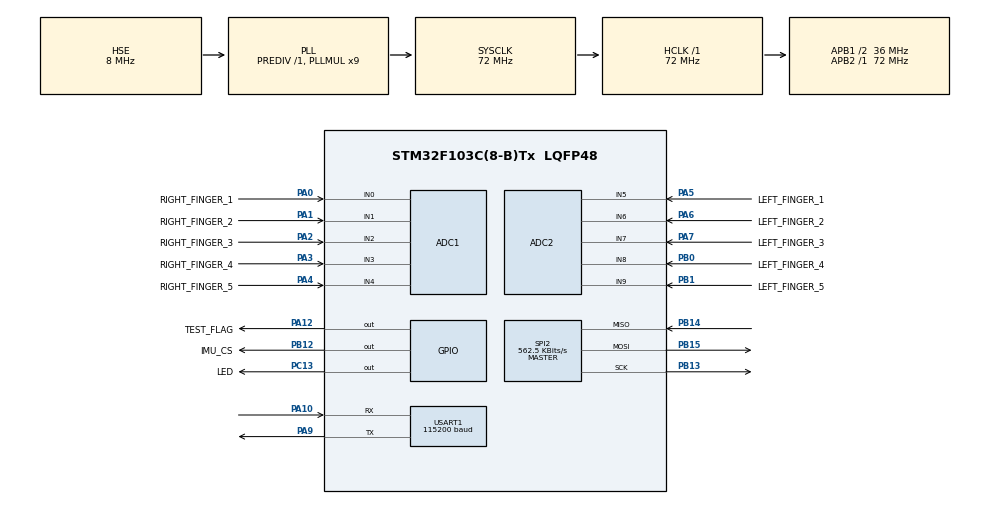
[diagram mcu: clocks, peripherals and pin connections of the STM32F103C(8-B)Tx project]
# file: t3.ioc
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ADC1.ContinuousConvMode=DISABLE
ADC1.DataAlign=ADC_DATAALIGN_RIGHT
ADC1.DiscontinuousConvMode=DISABLE
ADC1.EnableRegularConversion=DISABLE
ADC1.InjNumberOfConversion=0
ADC1.ScanConvMode=ADC_SCAN_DISABLE
ADC1.master=1
ADC2.Channel-0\#ChannelRegularConversion=ADC_CHANNEL_9
ADC2.ContinuousConvMode=DISABLE
ADC2.DataAlign=ADC_DATAALIGN_RIGHT
ADC2.DiscontinuousConvMode=DISABLE
ADC2.EnableAnalogWatchDog=false
ADC2.EnableRegularConversion=ENABLE
ADC2.ExternalTrigConv=ADC_SOFTWARE_START
ADC2.InjNumberOfConversion=0
ADC2.NbrOfConversion=1
ADC2.Rank-0\#ChannelRegularConversion=1
ADC2.SamplingTime-0\#ChannelRegularConversion=ADC_SAMPLETIME_1CYCLE_5
ADC2.ScanConvMode=ADC_SCAN_DISABLE
Mcu.Family=STM32F1
Mcu.Name=STM32F103C(8-B)Tx
Mcu.Package=LQFP48
NVIC.PriorityGroup=NVIC_PRIORITYGROUP_4
NVIC.TIM2_IRQn=true\:0\:0\:false\:false\:true\:true
PA0-WKUP.GPIO_Label=RIGHT_FINGER_1
PA0-WKUP.Signal=ADCx_IN0
PA1.GPIO_Label=RIGHT_FINGER_2
PA1.Signal=ADCx_IN1
PA10.Mode=Asynchronous
PA10.Signal=USART1_RX
PA12.GPIO_Label=TEST_FLAG
PA12.Signal=GPIO_Output
PA2.GPIO_Label=RIGHT_FINGER_3
PA2.Signal=ADCx_IN2
PA3.GPIO_Label=RIGHT_FINGER_4
PA3.Signal=ADCx_IN3
PA4.GPIO_Label=RIGHT_FINGER_5
PA4.Signal=ADCx_IN4
PA5.GPIO_Label=LEFT_FINGER_1
PA5.Signal=ADCx_IN5
PA6.GPIO_Label=LEFT_FINGER_2
PA6.Signal=ADCx_IN6
PA7.GPIO_Label=LEFT_FINGER_3
PA7.Signal=ADCx_IN7
PA9.Mode=Asynchronous
PA9.Signal=USART1_TX
PB0.GPIO_Label=LEFT_FINGER_4
PB0.Signal=ADCx_IN8
PB1.GPIO_Label=LEFT_FINGER_5
PB1.Signal=ADCx_IN9
PB12.GPIO_Label=IMU_CS
PB12.Signal=GPIO_Output
PB13.GPIO_Speed=GPIO_SPEED_FREQ_HIGH
PB13.Mode=Full_Duplex_Master
PB13.Signal=SPI2_SCK
PB14.GPIO_PuPd=GPIO_PULLDOWN
PB14.Mode=Full_Duplex_Master
PB14.Signal=SPI2_MISO
PB15.GPIO_Speed=GPIO_SPEED_FREQ_HIGH
PB15.Mode=Full_Duplex_Master
PB15.Signal=SPI2_MOSI
PC13-TAMPER-RTC.GPIO_Label=LED
PC13-TAMPER-RTC.Signal=GPIO_Output
PD0-OSC_IN.Mode=HSE-External-Oscillator
PD0-OSC_IN.Signal=RCC_OSC_IN
PD1-OSC_OUT.Mode=HSE-External-Oscillator
PD1-OSC_OUT.Signal=RCC_OSC_OUT
ProjectManager.HeapSize=0x200
ProjectManager.StackSize=0x400
ProjectManager.TargetToolchain=MDK-ARM V5
RCC.ADCPresc=RCC_ADCPCLK2_DIV6
RCC.AHBFreq_Value=72000000
RCC.APB1CLKDivider=RCC_HCLK_DIV2
RCC.APB1Freq_Value=36000000
RCC.APB1TimFreq_Value=72000000
RCC.APB2Freq_Value=72000000
RCC.APB2TimFreq_Value=72000000
RCC.HCLKFreq_Value=72000000
RCC.PLLMUL=RCC_PLL_MUL9
RCC.PLLSourceVirtual=RCC_PLLSOURCE_HSE
RCC.SYSCLKFreq_VALUE=72000000
RCC.SYSCLKSource=RCC_SYSCLKSOURCE_PLLCLK
RCC.USBFreq_Value=72000000
SH.ADCx_IN0.0=ADC1_IN0,IN0
SH.ADCx_IN1.0=ADC1_IN1,IN1
SH.ADCx_IN2.0=ADC1_IN2,IN2
SH.ADCx_IN3.0=ADC1_IN3,IN3
SH.ADCx_IN4.0=ADC1_IN4,IN4
SH.ADCx_IN5.0=ADC2_IN5,IN5
SH.ADCx_IN6.0=ADC2_IN6,IN6
SH.ADCx_IN7.0=ADC2_IN7,IN7
SH.ADCx_IN8.0=ADC2_IN8,IN8
SH.ADCx_IN9.0=ADC2_IN9,IN9
SPI2.BaudRatePrescaler=SPI_BAUDRATEPRESCALER_64
SPI2.CLKPhase=SPI_PHASE_1EDGE
SPI2.CLKPolarity=SPI_POLARITY_LOW
SPI2.CRCCalculation=SPI_CRCCALCULATION_DISABLE
SPI2.CalculateBaudRate=562.5 KBits/s
SPI2.Direction=SPI_DIRECTION_2LINES
SPI2.Mode=SPI_MODE_MASTER
SPI2.VirtualType=VM_MASTER
TIM2.Period=1000-1
TIM2.Prescaler=72-1
USART1.BaudRate=115200
USART1.VirtualMode=VM_ASYNC
VP_SYS_VS_ND.Mode=No_Debug
VP_TIM2_VS_ClockSourceINT.Mode=Internal
board=t3

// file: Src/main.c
/**
  ******************************************************************************
  * File Name          : main.c
  * Description        : Main program body
  ******************************************************************************
  ** This notice applies to any and all portions of this file
  * that are not between comment pairs USER CODE BEGIN and
  * USER CODE END. Other portions of this file, whether
  * inserted by the user or by software development tools
  * are owned by their respective copyright owners.
  *
  * COPYRIGHT(c) 2018 STMicroelectronics
  *
  * Redistribution and use in source and binary forms, with or without modification,
  * are permitted provided that the following conditions are met:
  *   1. Redistributions of source code must retain the above copyright notice,
  *      this list of conditions and the following disclaimer.
  *   2. Redistributions in binary form must reproduce the above copyright notice,
  *      this list of conditions and the following disclaimer in the documentation
  *      and/or other materials provided with the distribution.
  *   3. Neither the name of STMicroelectronics nor the names of its contributors
  *      may be used to endorse or promote products derived from this software
  *      without specific prior written permission.
  *
  * THIS SOFTWARE IS PROVIDED BY THE COPYRIGHT HOLDERS AND CONTRIBUTORS "AS IS"
  * AND ANY EXPRESS OR IMPLIED WARRANTIES, INCLUDING, BUT NOT LIMITED TO, THE
  * IMPLIED WARRANTIES OF MERCHANTABILITY AND FITNESS FOR A PARTICULAR PURPOSE ARE
  * DISCLAIMED. IN NO EVENT SHALL THE COPYRIGHT HOLDER OR CONTRIBUTORS BE LIABLE
  * FOR ANY DIRECT, INDIRECT, INCIDENTAL, SPECIAL, EXEMPLARY, OR CONSEQUENTIAL
  * DAMAGES (INCLUDING, BUT NOT LIMITED TO, PROCUREMENT OF SUBSTITUTE GOODS OR
  * SERVICES; LOSS OF USE, DATA, OR PROFITS; OR BUSINESS INTERRUPTION) HOWEVER
  * CAUSED AND ON ANY THEORY OF LIABILITY, WHETHER IN CONTRACT, STRICT LIABILITY,
  * OR TORT (INCLUDING NEGLIGENCE OR OTHERWISE) ARISING IN ANY WAY OUT OF THE USE
  * OF THIS SOFTWARE, EVEN IF ADVISED OF THE POSSIBILITY OF SUCH DAMAGE.
  *
  ******************************************************************************
  */

#include "main.h"
#include "stm32f1xx_hal.h"
#include "adc.h"
#include "spi.h"
#include "tim.h"
#include "usart.h"
#include "gpio.h"

/* USER CODE BEGIN Includes */
#include "attitude.h"
#include "transmitter.h"
/* USER CODE END Includes */

/* USER CODE BEGIN PV */
/* Private variables ---------------------------------------------------------*/

/* USER CODE END PV */

void SystemClock_Config(void);

/* USER CODE BEGIN PFP */
/* Private function prototypes -----------------------------------------------*/

/* USER CODE END PFP */

int main(void)
{

  /* MCU Configuration----------------------------------------------------------*/

  /* Reset of all peripherals, Initializes the Flash interface and the Systick. */
  HAL_Init();

  /* Configure the system clock */
  SystemClock_Config();

  /* Initialize all configured peripherals */
  MX_GPIO_Init();
  MX_USART1_UART_Init();
  MX_ADC1_Init();
  MX_ADC2_Init();
  MX_SPI2_Init();
  MX_TIM2_Init();

  /* USER CODE BEGIN 2 */
	attitude_init();
	led_off();

	HAL_TIM_Base_Start_IT(&htim2);
	transmitter_init();

  /* USER CODE END 2 */

  /* Infinite loop */
  while (1)
  {

  /* USER CODE BEGIN 3 */
		transmitter_send_imu_data(get_acc(), get_gyro(), get_quat());
		HAL_Delay(14);
  }
  /* USER CODE END 3 */

}

/** System Clock Configuration
*/
void SystemClock_Config(void)
{

  RCC_OscInitTypeDef RCC_OscInitStruct;
  RCC_ClkInitTypeDef RCC_ClkInitStruct;
  RCC_PeriphCLKInitTypeDef PeriphClkInit;

    /**Initializes the CPU, AHB and APB busses clocks
    */
  RCC_OscInitStruct.OscillatorType = RCC_OSCILLATORTYPE_HSE;
  RCC_OscInitStruct.HSEState = RCC_HSE_ON;
  RCC_OscInitStruct.HSEPredivValue = RCC_HSE_PREDIV_DIV1;
  RCC_OscInitStruct.HSIState = RCC_HSI_ON;
  RCC_OscInitStruct.PLL.PLLState = RCC_PLL_ON;
  RCC_OscInitStruct.PLL.PLLSource = RCC_PLLSOURCE_HSE;
  RCC_OscInitStruct.PLL.PLLMUL = RCC_PLL_MUL9;
  if (HAL_RCC_OscConfig(&RCC_OscInitStruct) != HAL_OK)
  {
    _Error_Handler(__FILE__, __LINE__);
  }

    /**Initializes the CPU, AHB and APB busses clocks
    */
  RCC_ClkInitStruct.ClockType = RCC_CLOCKTYPE_HCLK|RCC_CLOCKTYPE_SYSCLK
                              |RCC_CLOCKTYPE_PCLK1|RCC_CLOCKTYPE_PCLK2;
  RCC_ClkInitStruct.SYSCLKSource = RCC_SYSCLKSOURCE_PLLCLK;
  RCC_ClkInitStruct.AHBCLKDivider = RCC_SYSCLK_DIV1;
  RCC_ClkInitStruct.APB1CLKDivider = RCC_HCLK_DIV2;
  RCC_ClkInitStruct.APB2CLKDivider = RCC_HCLK_DIV1;

  if (HAL_RCC_ClockConfig(&RCC_ClkInitStruct, FLASH_LATENCY_2) != HAL_OK)
  {
    _Error_Handler(__FILE__, __LINE__);
  }

  PeriphClkInit.PeriphClockSelection = RCC_PERIPHCLK_ADC;
  PeriphClkInit.AdcClockSelection = RCC_ADCPCLK2_DIV6;
  if (HAL_RCCEx_PeriphCLKConfig(&PeriphClkInit) != HAL_OK)
  {
    _Error_Handler(__FILE__, __LINE__);
  }

    /**Configure the Systick interrupt time
    */
  HAL_SYSTICK_Config(HAL_RCC_GetHCLKFreq()/1000);

    /**Configure the Systick
    */
  HAL_SYSTICK_CLKSourceConfig(SYSTICK_CLKSOURCE_HCLK);

  /* SysTick_IRQn interrupt configuration */
  HAL_NVIC_SetPriority(SysTick_IRQn, 0, 0);
}

/* USER CODE BEGIN 4 */

void HAL_TIM_PeriodElapsedCallback(TIM_HandleTypeDef *htim)
{
	if(htim->Instance == htim2.Instance)
	{
		set_test_flag();
		attitude_updata();
		reset_test_flag();
//		toggle_test_flag();
//		HAL_GPIO_TogglePin(TEST_FLAG_GPIO_Port, TEST_FLAG_Pin);
	}

}

/* USER CODE END 4 */

void _Error_Handler(char * file, int line)
{
  while(1)
  {
  }
}

/************************ (C) COPYRIGHT STMicroelectronics *****END OF FILE****/
